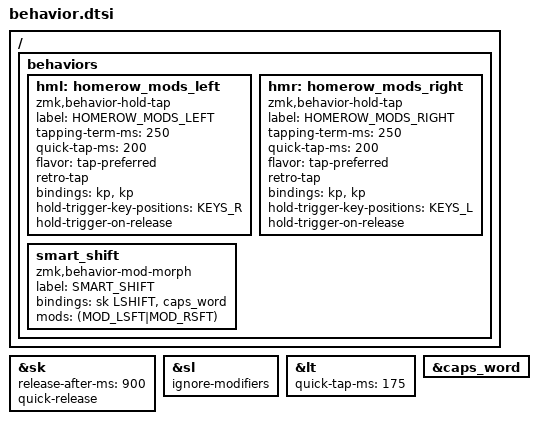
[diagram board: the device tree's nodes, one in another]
/* Custom behaviors */
&sk {
    release-after-ms = <900>;
    quick-release;
};
&sl {
    ignore-modifiers;
};
&lt {
    quick-tap-ms = <175>;
};
&caps_word {
    /delete-property/ ignore-modifiers;
};

/* Homerow mods */
#define KEYS_L 0 1 2 3 4 5 12 13 14 15 16 17 24 25 26 27 28 29
#define KEYS_R 6 7 8 9 10 11 18 19 20 21 22 23 30 31 32 33 34 35

/ {
	behaviors {
		hml: homerow_mods_left {
			compatible = "zmk,behavior-hold-tap";
			label = "HOMEROW_MODS_LEFT";
			#binding-cells = <2>;
			tapping-term-ms = <250>;
			quick-tap-ms = <200>;
			flavor = "tap-preferred";
			retro-tap;
			bindings = <&kp>, <&kp>;
			hold-trigger-key-positions = <KEYS_R>;
			hold-trigger-on-release;
		};
		hmr: homerow_mods_right {
			compatible = "zmk,behavior-hold-tap";
			label = "HOMEROW_MODS_RIGHT";
			#binding-cells = <2>;
			tapping-term-ms = <250>;
			quick-tap-ms = <200>;
			flavor = "tap-preferred";
			retro-tap;
			bindings = <&kp>, <&kp>;
			hold-trigger-key-positions = <KEYS_L>;
			hold-trigger-on-release;
		};
		smart_shift: smart_shift {
			compatible = "zmk,behavior-mod-morph";
			label = "SMART_SHIFT";
			#binding-cells = <0>;
			bindings = <&sk LSHIFT>, <&caps_word>;
			mods = <(MOD_LSFT|MOD_RSFT)>;
		};
	};
};
